VERSION ""

NS_ :

BS_:

BU_: VCU BMS LeanAngle Motor Rear Front BrakeSensors Radiator Inverter Temperature

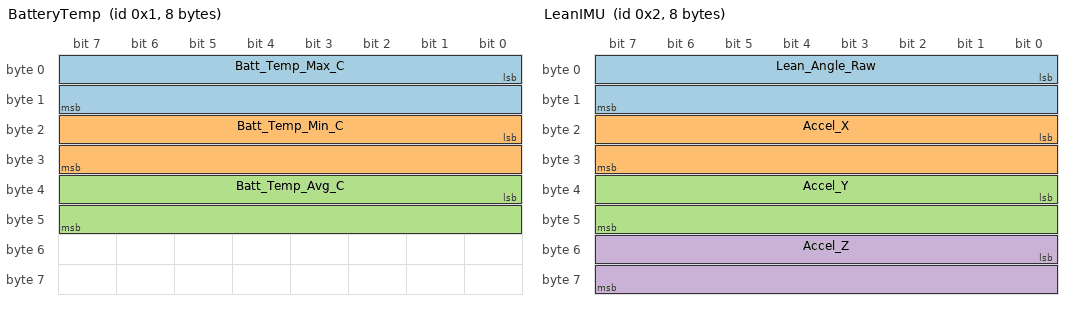
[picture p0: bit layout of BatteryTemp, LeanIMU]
BO_ 1 BatteryTemp: 8 BMS
 SG_ Batt_Temp_Max_C : 0|16@1- (0.1,0) [-40|100] "degC" VCU
 SG_ Batt_Temp_Min_C : 16|16@1- (0.1,0) [-40|100] "degC" VCU
 SG_ Batt_Temp_Avg_C : 32|16@1- (0.1,0) [-40|100] "degC" VCU

BO_ 2 LeanIMU: 8 LeanAngle
 SG_ Lean_Angle_Raw : 0|16@1- (1,0) [-32768|32767] "raw" VCU
 SG_ Accel_X : 16|16@1- (0.001,0) [-16|16] "g" VCU
 SG_ Accel_Y : 32|16@1- (0.001,0) [-16|16] "g" VCU
 SG_ Accel_Z : 48|16@1- (0.001,0) [-16|16] "g" VCU

BO_ 3 PowertrainRotationalSpeed: 8 Motor
 SG_ Powertrain_RPM_Raw : 0|16@1+ (1,0) [0|65535] "rpm" VCU

BO_ 4 RearWheelSpeed: 8 Rear
 SG_ Rear_Speed_kmh : 0|16@1+ (0.1,0) [0|300] "km/h" VCU

BO_ 5 FrontWheelSpeed: 8 Front
 SG_ Front_Speed_kmh : 0|16@1+ (0.1,0) [0|300] "km/h" VCU

BO_ 6 BrakePressure: 8 BrakeSensors
 SG_ Front_Brake_Pressure_Raw : 0|16@1+ (1,0) [0|65535] "raw" VCU
 SG_ Rear_Brake_Pressure_Raw : 16|16@1+ (1,0) [0|65535] "raw" VCU

BO_ 7 CoolingTemp: 8 Radiator
 SG_ Coolant_In_C : 0|16@1- (0.1,0) [-40|150] "degC" VCU
 SG_ Coolant_Out_C : 16|16@1- (0.1,0) [-40|150] "degC" VCU

BO_ 8 MotorTemp: 8 Motor
 SG_ Motor_Temp_C : 0|16@1- (0.1,0) [-40|200] "degC" VCU

BO_ 9 InverterTemp: 8 Inverter
 SG_ Inverter_Temp_C : 0|16@1- (0.1,0) [-40|200] "degC" VCU

BO_ 10 RadiatorTemp: 8 Radiator
 SG_ Radiator_Temp_Raw : 0|16@1- (1,0) [-32768|32767] "raw" VCU

BO_ 11 SuspensionTravel: 8 Front
 SG_ Front_Suspension_Travel_Raw : 0|16@1+ (1,0) [0|65535] "raw" VCU

BO_ 12 MotorRPM: 8 Motor
 SG_ Motor_RPM : 0|16@1+ (1,0) [0|20000] "rpm" VCU

BO_ 13 CoolantPumpRPM: 8 Radiator
 SG_ Coolant_Pump_RPM_Raw : 0|16@1+ (1,0) [0|65535] "rpm" VCU

BO_ 14 CoolantPumpFlow: 8 Radiator
 SG_ Coolant_Flow_Raw : 0|16@1+ (1,0) [0|65535] "raw" VCU

BO_ 15 IndividualBatteryTemp: 8 Temperature
 SG_ Individual_Batt_Temp_Raw : 0|16@1- (1,0) [-32768|32767] "raw" VCU

BO_ 16 BatteryVoltage: 8 BMS
 SG_ Pack_Voltage_V : 0|16@1+ (0.1,0) [0|500] "V" VCU

BO_ 17 BatteryCurrent: 8 BMS
 SG_ Pack_Current_A : 0|16@1- (0.1,0) [-500|500] "A" VCU

BA_DEF_ BO_ "GenMsgCycleTime" INT 0 10000;
BA_DEF_DEF_ "GenMsgCycleTime" 100;

BA_ "GenMsgCycleTime" BO_ 2 10;
BA_ "GenMsgCycleTime" BO_ 3 10;
BA_ "GenMsgCycleTime" BO_ 4 20;
BA_ "GenMsgCycleTime" BO_ 5 20;
BA_ "GenMsgCycleTime" BO_ 6 20;
BA_ "GenMsgCycleTime" BO_ 11 20;
BA_ "GenMsgCycleTime" BO_ 12 10;
BA_ "GenMsgCycleTime" BO_ 17 20;
